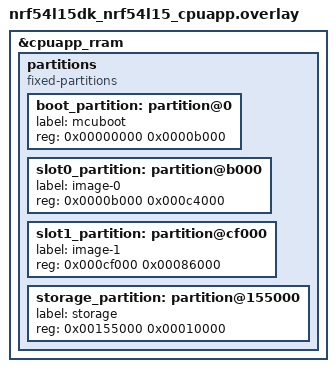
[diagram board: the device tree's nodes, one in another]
/*
 * Copyright (c) 2025 Nordic Semiconductor ASA
 *
 * SPDX-License-Identifier: LicenseRef-Nordic-5-Clause
 */

/delete-node/ &boot_partition;
/delete-node/ &slot0_partition;
/delete-node/ &slot1_partition;
/delete-node/ &storage_partition;

&cpuapp_rram {
	partitions {
		compatible = "fixed-partitions";
		#address-cells = <1>;
		#size-cells = <1>;

		boot_partition: partition@0 {
			label = "mcuboot";
			reg = <0x00000000 0x0000b000>;
		};

		slot0_partition: partition@b000 {
			label = "image-0";
			reg = <0x0000b000 0x000c4000>;
		};

		slot1_partition: partition@cf000 {
			label = "image-1";
			reg = <0x000cf000 0x00086000>;
		};

		storage_partition: partition@155000 {
			label = "storage";
			reg = <0x00155000 0x00010000>;
		};
	};
};
